# AVR64EA28 device description
Architecture: AVR8X; Family: AVR
Registers are 8-bit, read-write, reset 0x0 unless marked. A register's access mark holds for its fields unless they carry their own. Offsets are from the block's base; [hi:lo] are bit positions; {n}, {i} and the like mark numbered series; 'fields as' and 'values as' point back to an identical list; <NAME> marks a mode.

## SLPCTRL — Sleep Controller
Instances: SLPCTRL 0x0050
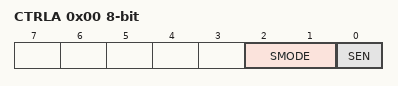
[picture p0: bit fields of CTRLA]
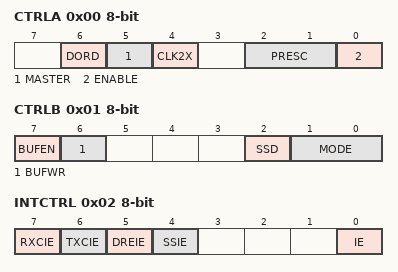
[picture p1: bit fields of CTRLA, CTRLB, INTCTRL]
0x00 CTRLA — Control A
  [2:1] SMODE — Sleep mode
    0=IDLE (Idle mode); 1=STDBY (Standby Mode); 2=PDOWN (Power-down Mode)
  [0] SEN — Sleep enable

## SPI — Serial Peripheral Interface
Instances: SPI0 0x0940
0x00 CTRLA — Control A
  [6] DORD — Data Order Setting
  [5] MASTER — Host Operation Enable
  [4] CLK2X — Enable Double Speed
  [2:1] PRESC — Prescaler
    0=DIV4 (System Clock / 4); 1=DIV16 (System Clock / 16); 2=DIV64 (System Clock / 64); 3=DIV128 (System Clock / 128)
  [0] ENABLE — Enable Module
0x01 CTRLB — Control B
  [7] BUFEN — Buffer Mode Enable
  [6] BUFWR — Buffer Mode Wait for Receive
  [2] SSD — SPI Select Disable
  [1:0] MODE — SPI Mode
    {v}=SPI Mode {v} (v=0..3)
0x02 INTCTRL — Interrupt Control
  [7] RXCIE — Receive Complete Interrupt Enable
  [6] TXCIE — Transfer Complete Interrupt Enable
  [5] DREIE — Data Register Empty Interrupt Enable
  [4] SSIE — SPI Select Trigger Interrupt Enable
  [0] IE — Interrupt Enable
0x03 INTFLAGS (modes: DEFAULT when SPI.CTRLB.BUFEN=0; BUFFERED when SPI.CTRLB.BUFEN=1) — Interrupt Flags
  [7] RXCIF <BUFFERED> — Receive Complete Interrupt Flag
  [6] TXCIF <BUFFERED> — Transfer Complete Interrupt Flag
  [5] DREIF <BUFFERED> — Data Register Empty Interrupt Flag
  [4] SSIF <BUFFERED> — SPI Select Trigger Interrupt Flag
  [0] BUFOVF <BUFFERED> — Buffer Overflow
  [7] IF <DEFAULT> — Interrupt Flag
  [6] WRCOL <DEFAULT> — Write Collision
0x04 DATA reset not defined

## SYSCFG — System Configuration Registers
Instances: SYSCFG 0x0F00
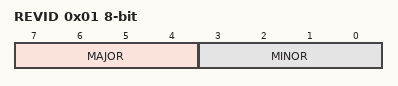
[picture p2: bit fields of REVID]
0x01 REVID ro reset not defined — Revision ID
  [7:4] MAJOR — Major Revision
  [3:0] MINOR — Minor Revision
0x04 OCDMCTRL reset not defined — OCD Message Control
  [7:0] OCDM — OCD Message
0x05 OCDMSTATUS — OCD Message Status
  [0] VALID — OCD Message Valid

## TCB — 16-bit Timer Type B
Instances: TCB0 0x0B00, TCB1 0x0B10, TCB2 0x0B20
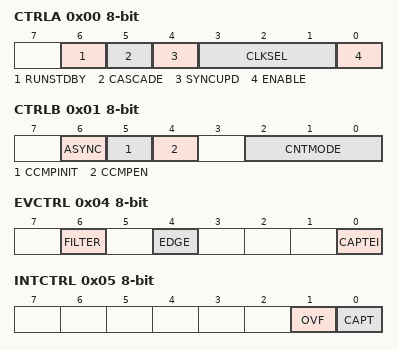
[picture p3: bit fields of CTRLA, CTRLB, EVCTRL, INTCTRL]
0x00 CTRLA — Control A
  [6] RUNSTDBY — Run Standby
  [5] CASCADE — Cascade two timers
  [4] SYNCUPD — Synchronize Update
  [3:1] CLKSEL — Clock Select
    0=DIV1 (CLK_PER); 1=DIV2 (CLK_PER/2); 2=TCA0 (Use CLK_TCA from TCA0); 3=TCA1 (Use CLK_TCA from TCA1); 7=EVENT (Count on event edge)
  [0] ENABLE
0x01 CTRLB — Control Register B
  [6] ASYNC — Asynchronous Enable
  [5] CCMPINIT — Pin Initial State
  [4] CCMPEN — Pin Output Enable
  [2:0] CNTMODE — Timer Mode
    0=INT (Periodic Interrupt); 1=TIMEOUT (Periodic Timeout); 2=CAPT (Input Capture Event); 3=FRQ (Input Capture Frequency measurement); 4=PW (Input Capture Pulse-Width measurement); 5=FRQPW (Input Capture Frequency and Pulse-Width measurement); 6=SINGLE (Single Shot); 7=PWM8 (8-bit PWM)
0x04 EVCTRL — Event Control
  [6] FILTER — Input Capture Noise Cancellation Filter
  [4] EDGE — Event Edge
  [0] CAPTEI — Event Input Enable
0x05 INTCTRL — Interrupt Control
  [1] OVF — Overflow
  [0] CAPT — Capture or Timeout
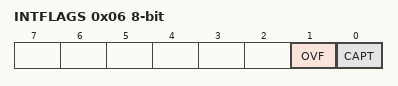
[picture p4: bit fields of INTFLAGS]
0x06 INTFLAGS — Interrupt Flags
  [1] OVF — Overflow
  [0] CAPT — Capture or Timeout
0x07 STATUS ro
  [0] RUN
0x08 DBGCTRL — Debug Control
  [0] DBGRUN — Debug Run
0x09 TEMP reset not defined — Temporary Value
0x0A CNT 16-bit — Count
0x0C CCMP 16-bit reset not defined — Compare or Capture

## TWI — Two-Wire Interface
Instances: TWI0 0x0900
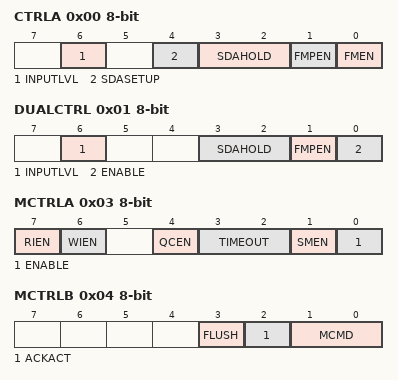
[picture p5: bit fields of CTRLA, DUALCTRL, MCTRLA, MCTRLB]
0x00 CTRLA — Control A
  [6] INPUTLVL — Input voltage transition level
    0=I2C (I2C input voltage transition level); 1=SMBUS (SMBus 3.0 input voltage transition level)
  [4] SDASETUP — SDA Setup Time
    0=4CYC (SDA setup time is four clock cycles); 1=8CYC (SDA setup time is eight clock cycle)
  [3:2] SDAHOLD — SDA Hold Time
    0=OFF (No SDA Hold Delay); 1=50NS (Short SDA hold time); 2=300NS (Meets SMBUS 2.0 specification under typical conditions); 3=500NS (Meets SMBUS 2.0 specificaiton across all corners)
  [1] FMPEN — Fast-mode Plus Enable
    0=OFF (Operating in Standard-mode or Fast-mode); 1=ON (Operating in Fast-mode Plus)
  [0] FMEN — Fast-mode Enable
    0=OFF (SCL duty cycle operating according to Sm specification); 1=ON (SCL duty cycle operating according to Fm specification)
0x01 DUALCTRL — Dual Mode Control
  [6] INPUTLVL — Input voltage transition level
    values as CTRLA.INPUTLVL
  [3:2] SDAHOLD — SDA Hold Time
    values as CTRLA.SDAHOLD
  [1] FMPEN — Fast-mode Plus Enable
    values as CTRLA.FMPEN
  [0] ENABLE
0x02 DBGCTRL — Debug Control
  [0] DBGRUN — Debug Run
    0=HALT (The peripheral is halted in Break Debug mode and ignores events); 1=RUN (The peripheral will continue to run in Break Debug mode when the CPU is halted)
0x03 MCTRLA — Host Control A
  [7] RIEN — Read Interrupt Enable
  [6] WIEN — Write Interrupt Enable
  [4] QCEN — Quick Command Enable
  [3:2] TIMEOUT — Inactive Bus Time-Out
    0=DISABLED (Bus time-out disabled. I2C.); 1=50US (50us - SMBus); 2=100US; 3=200US
  [1] SMEN — Smart Mode Enable
  [0] ENABLE
0x04 MCTRLB — Host Control B
  [3] FLUSH
  [2] ACKACT — Acknowledge Action
    0=ACK (Send ACK); 1=NACK (Send NACK)
  [1:0] MCMD — Command
    0=NOACT (No action); 1=REPSTART (Execute Acknowledge Action followed by repeated Start.); 2=RECVTRANS (Execute Acknowledge Action followed by a byte read/write operation. Read/write is defined by DIR.); 3=STOP (Execute Acknowledge Action followed by issuing a Stop condition.)
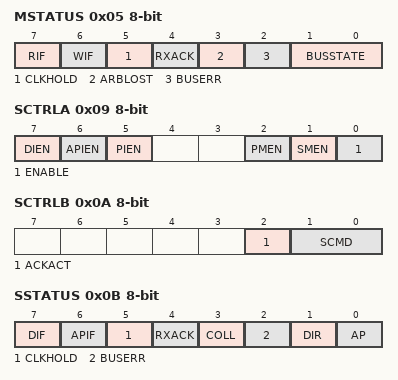
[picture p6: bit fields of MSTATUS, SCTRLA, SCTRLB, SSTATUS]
0x05 MSTATUS — Host STATUS
  [7] RIF — Read Interrupt Flag
  [6] WIF — Write Interrupt Flag
  [5] CLKHOLD — Clock Hold
  [4] RXACK — Received Acknowledge
  [3] ARBLOST — Arbitration Lost
  [2] BUSERR — Bus Error
  [1:0] BUSSTATE
    0=UNKNOWN (Unknown bus state); 1=IDLE (Bus is idle); 2=OWNER (This TWI controls the bus); 3=BUSY (The bus is busy)
0x06 MBAUD — Host Baud Rate
  [7:0] BAUD — Baud Rate
0x07 MADDR — Host Address
  [7:0] ADDR — Address
0x08 MDATA — Host Data
  [7:0] DATA
0x09 SCTRLA — Client Control A
  [7] DIEN — Data Interrupt Enable
  [6] APIEN — Address or Stop Interrupt Enable
  [5] PIEN — Stop Interrupt Enable
  [2] PMEN — Address Recognition Mode
  [1] SMEN — Smart Mode Enable
  [0] ENABLE
0x0A SCTRLB — Client Control B
  [2] ACKACT — Acknowledge Action
    0=ACK (Send ACK); 1=NACK (Send NACK)
  [1:0] SCMD — Command
    0=NOACT (No Action); 2=COMPTRANS (Complete transaction); 3=RESPONSE (Used in response to an interrupt)
0x0B SSTATUS — Client Status
  [7] DIF — Data Interrupt Flag
  [6] APIF — Address or Stop Interrupt Flag
  [5] CLKHOLD — Clock Hold
  [4] RXACK — Received Acknowledge
  [3] COLL — Collision
  [2] BUSERR — Bus Error
  [1] DIR — Read/Write Direction
  [0] AP — Address or Stop
    0=STOP (A Stop condition generated the interrupt on APIF flag); 1=ADR (Address detection generated the interrupt on APIF flag)
0x0C SADDR — Client Address
  [7:0] ADDR — Address
0x0D SDATA — Client Data
  [7:0] DATA
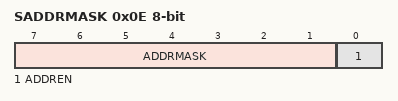
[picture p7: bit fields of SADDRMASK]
0x0E SADDRMASK — Client Address Mask
  [7:1] ADDRMASK — Address Mask
  [0] ADDREN — Address Mask Enable
